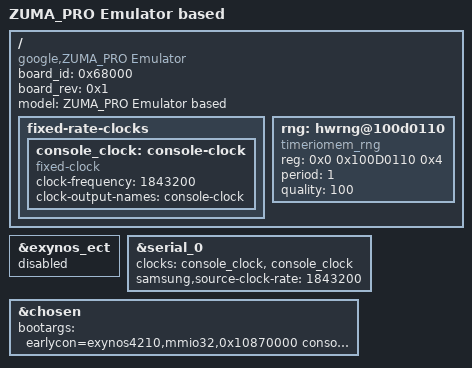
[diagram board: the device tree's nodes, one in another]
// SPDX-License-Identifier: GPL-2.0-only
/*
 * Zuma on emulator device tree source
 *
 * Copyright 2020-2021 Google LLC
 */

/dts-v1/;
/plugin/;

#include "zumapro-emul-display.dtsi"

/ {
	board_id = <0x68000>;
	board_rev = <0x1>;
	fragment@boardbase {
		target-path="/";
		__overlay__ {
			model = "ZUMA_PRO Emulator based";
			compatible = "google,ZUMA_PRO Emulator", "google,ZUMA_PRO";
			fixed-rate-clocks {
				console_clock: console-clock {
					compatible = "fixed-clock";
					#clock-cells = <0>;
					clock-frequency = <1843200>;
					clock-output-names = "console-clock";
				};
			};
		};
	};
};

&exynos_ect {
	status = "disabled";
};

&serial_0 {
	status = "okay";
	clocks = <&console_clock>, <&console_clock>;
	samsung,source-clock-rate = <1843200>;
};

&chosen {
	bootargs = "earlycon=exynos4210,mmio32,0x10870000 console=ttySAC0,115200n8 clocksource=arch_sys_counter root=/dev/ram0 rw ramdisk_size=65536 initrd=0x84000000,32M androidboot.hardware=zumapro androidboot.hardware.platform=zumapro androidboot.selinux=permissive androidboot.debug_level=0x4948 firmware_class.path=/vendor/firmware clk_ignore_unused loop.max_part=7 coherent_pool=4M no_console_suspend nokaslr softlockup_panic=1 sysrq_always_enabled mem=512M  androidboot.first_stage_console=1 androidboot.force_normal_boot=1 slub_debug=- printk.devkmsg=on arm64.nopauth arm64.nomte kasan=off panic_on_warm=1 drm.debug=0x17 exynos_drm.panel_name=samsung-emul";
};

/ {
	fragment@hwrng {
		target-path = "/";
		__overlay__ {
			rng: hwrng@100d0110 {
				compatible = "timeriomem_rng";
				reg = <0x0 0x100D0110 0x4>;
				period = <1>;
				quality = <100>;
				status = "okay";
			};
		};
	};
};

